VERSION "1.0"

NS_ :

BS_:

BU_: VCU BMS DCDC SIG

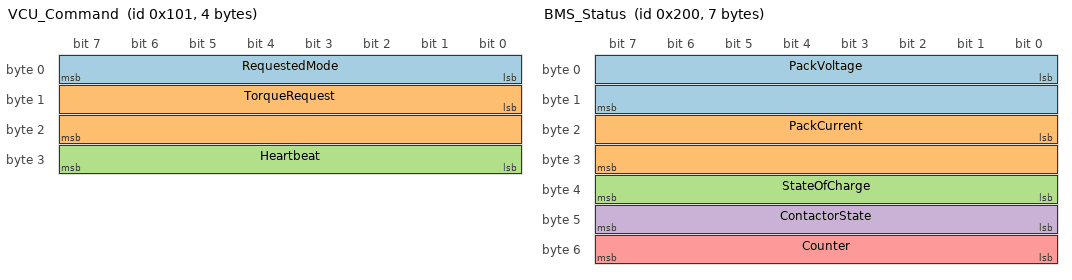
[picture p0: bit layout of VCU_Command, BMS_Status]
BO_ 257 VCU_Command: 4 VCU
 SG_ RequestedMode : 0|8@1+ (1,0) [0|3] "" BMS,DCDC
 SG_ TorqueRequest : 8|16@1- (0.1,0) [-1000|1000] "Nm" BMS,DCDC
 SG_ Heartbeat : 24|8@1+ (1,0) [0|255] "" BMS,DCDC

BO_ 512 BMS_Status: 7 BMS
 SG_ PackVoltage : 0|16@1+ (0.1,0) [0|1000] "V" VCU,DCDC
 SG_ PackCurrent : 16|16@1- (0.1,0) [-1000|1000] "A" VCU,DCDC
 SG_ StateOfCharge : 32|8@1+ (0.5,0) [0|100] "%" VCU,DCDC
 SG_ ContactorState : 40|8@1+ (1,0) [0|3] "" VCU,DCDC
 SG_ Counter : 48|8@1+ (1,0) [0|255] "" VCU,DCDC

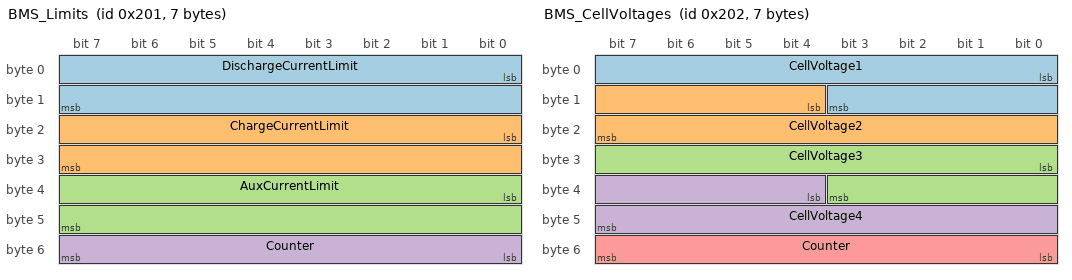
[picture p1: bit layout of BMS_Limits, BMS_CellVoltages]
BO_ 513 BMS_Limits: 7 BMS
 SG_ DischargeCurrentLimit : 0|16@1+ (0.01,0) [0|655.35] "A" VCU,DCDC
 SG_ ChargeCurrentLimit : 16|16@1+ (0.01,0) [0|655.35] "A" VCU,DCDC
 SG_ AuxCurrentLimit : 32|16@1+ (0.01,0) [0|655.35] "A" VCU,DCDC
 SG_ Counter : 48|8@1+ (1,0) [0|255] "" VCU,DCDC

BO_ 514 BMS_CellVoltages: 7 BMS
 SG_ CellVoltage1 : 0|12@1+ (0.001,2) [2|6.095] "V" VCU
 SG_ CellVoltage2 : 12|12@1+ (0.001,2) [2|6.095] "V" VCU
 SG_ CellVoltage3 : 24|12@1+ (0.001,2) [2|6.095] "V" VCU
 SG_ CellVoltage4 : 36|12@1+ (0.001,2) [2|6.095] "V" VCU
 SG_ Counter : 48|8@1+ (1,0) [0|255] "" VCU

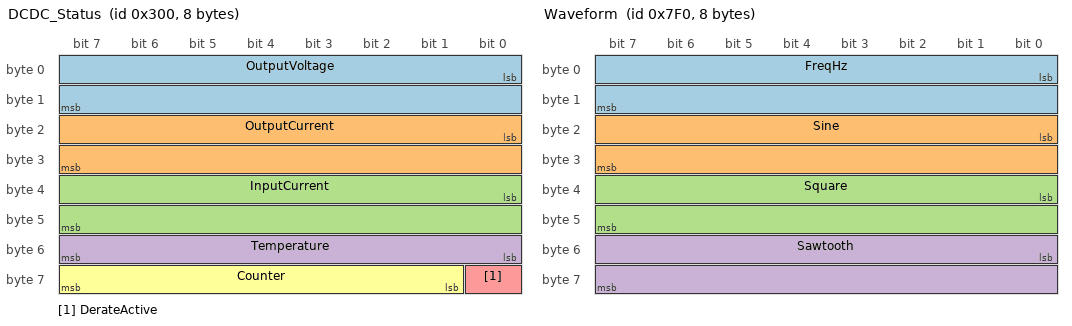
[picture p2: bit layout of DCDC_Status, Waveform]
BO_ 768 DCDC_Status: 8 DCDC
 SG_ OutputVoltage : 0|16@1+ (0.01,0) [0|655.35] "V" VCU,BMS
 SG_ OutputCurrent : 16|16@1+ (0.1,0) [0|6553.5] "A" VCU,BMS
 SG_ InputCurrent : 32|16@1+ (0.01,0) [0|655.35] "A" VCU,BMS
 SG_ Temperature : 48|8@1+ (1,-40) [-40|215] "degC" VCU,BMS
 SG_ DerateActive : 56|1@1+ (1,0) [0|1] "" VCU,BMS
 SG_ Counter : 57|7@1+ (1,0) [0|127] "" VCU,BMS

BO_ 2032 Waveform: 8 SIG
 SG_ FreqHz : 0|16@1+ (0.01,0) [0|655.35] "Hz" VCU
 SG_ Sine : 16|16@1- (0.001,0) [-1|1] "" VCU
 SG_ Square : 32|16@1- (0.001,0) [-1|1] "" VCU
 SG_ Sawtooth : 48|16@1- (0.001,0) [-1|1] "" VCU

CM_ BU_ VCU "Vehicle control unit. Commands the operating mode and carries the bus heartbeat.";
CM_ BU_ BMS "Battery management system. Reports pack state and publishes the current limits the DC-DC must respect.";
CM_ BU_ DCDC "DC-DC converter. Steps the high-voltage pack down to the 12 V rail, within the BMS current limit.";
CM_ BO_ 257 "Operating mode request and heartbeat. The BMS and DC-DC both follow the commanded mode.";
CM_ BO_ 512 "Pack-level measurements and contactor state.";
CM_ BO_ 513 "The current envelope the pack allows right now. AuxCurrentLimit bounds what the DC-DC may draw from the pack.";
CM_ BO_ 514 "Per-cell voltages. Four cells, one frame, no multiplexing.";
CM_ BO_ 768 "DC-DC converter state. InputCurrent is drawn from the pack and must stay within BMS_Limits.AuxCurrentLimit.";
CM_ SG_ 257 TorqueRequest "Positive is drive, negative is regenerative braking.";
CM_ SG_ 512 PackCurrent "Positive is discharge, negative is charge.";
CM_ SG_ 513 DischargeCurrentLimit "Pack-level ceiling for traction draw.";
CM_ SG_ 513 AuxCurrentLimit "Pack current the DC-DC converter may draw. The BMS reduces it while charging.";
CM_ SG_ 768 InputCurrent "Current drawn from the high-voltage pack.";
CM_ SG_ 768 DerateActive "Set when the converter is limiting output because of temperature.";

CM_ BO_ 2032 "Signal generator: one phase, chirped 1 to 100 Hz over 20 s, as sine, square and sawtooth. Lowest-priority ID on the bus.";
BA_DEF_ BO_ "GenMsgCycleTime" INT 0 10000;
BA_DEF_DEF_ "GenMsgCycleTime" 0;
BA_ "GenMsgCycleTime" BO_ 257 100;
BA_ "GenMsgCycleTime" BO_ 512 100;
BA_ "GenMsgCycleTime" BO_ 513 100;
BA_ "GenMsgCycleTime" BO_ 514 500;
BA_ "GenMsgCycleTime" BO_ 768 50;
BA_ "GenMsgCycleTime" BO_ 2032 2;

VAL_ 257 RequestedMode 0 "Standby" 1 "Drive" 2 "Charge" 3 "Fault" ;
VAL_ 512 ContactorState 0 "Open" 1 "Precharge" 2 "Closed" 3 "Fault" ;
VAL_ 768 DerateActive 0 "Inactive" 1 "Active" ;
